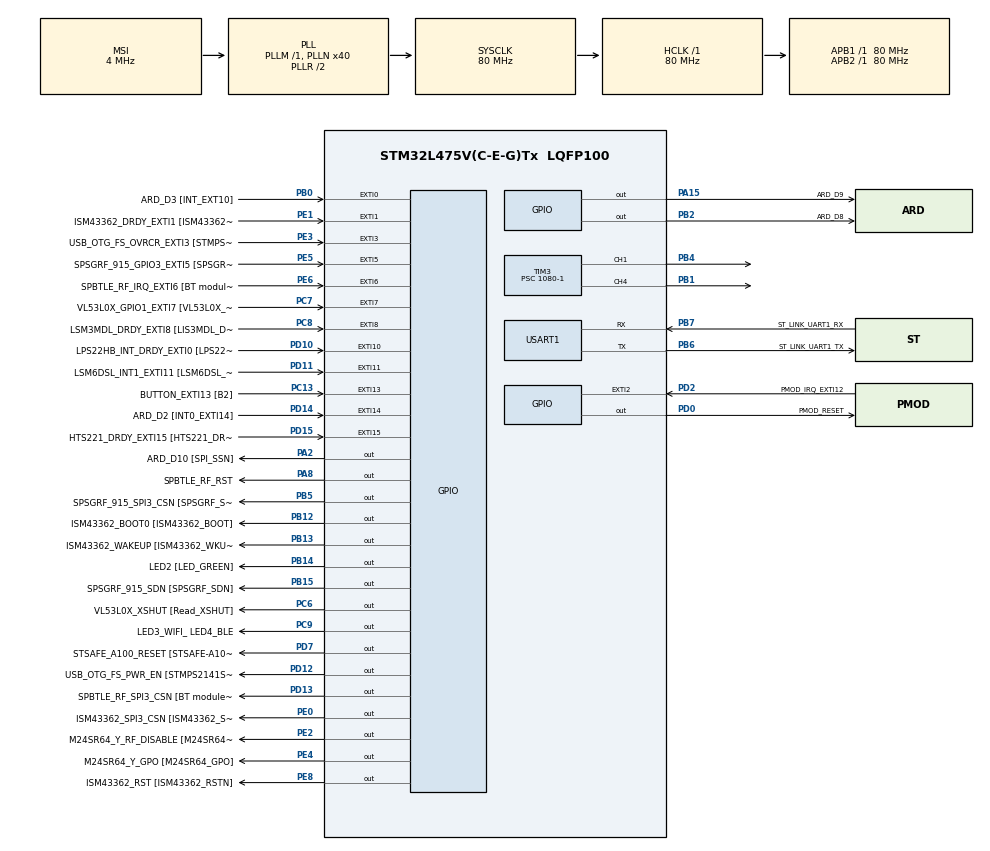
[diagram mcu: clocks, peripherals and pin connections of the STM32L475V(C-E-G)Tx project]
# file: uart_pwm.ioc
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Mcu.Family=STM32L4
Mcu.Name=STM32L475V(C-E-G)Tx
Mcu.Package=LQFP100
NVIC.EXTI15_10_IRQn=true\:0\:0\:false\:false\:true\:true\:true
NVIC.EXTI9_5_IRQn=true\:0\:0\:false\:false\:true\:true\:true
NVIC.PriorityGroup=NVIC_PRIORITYGROUP_4
PA0.GPIO_Label=ARD_D1 [UART4_TX]
PA0.Signal=UART4_TX
PA1.GPIO_Label=ARD_D0 [UART4_RX]
PA1.Signal=UART4_RX
PA10.GPIO_Label=USB_OTG_FS_ID
PA10.Signal=USB_OTG_FS_ID
PA11.GPIO_Label=USB_OTG_FS_DM
PA11.Signal=USB_OTG_FS_DM
PA12.GPIO_Label=USB_OTG_FS_DP
PA12.Signal=USB_OTG_FS_DP
PA13\ (JTMS-SWDIO).GPIO_Label=SYS_JTMS_SWDIO
PA13\ (JTMS-SWDIO).Signal=SYS_JTMS-SWDIO
PA14\ (JTCK-SWCLK).GPIO_Label=SYS_JTCK_SWCLK
PA14\ (JTCK-SWCLK).Signal=SYS_JTCK-SWCLK
PA15\ (JTDI).GPIO_Label=ARD_D9
PA15\ (JTDI).Signal=GPIO_Output
PA2.GPIO_Label=ARD_D10 [SPI_SSN]
PA2.Signal=GPIO_Output
PA3.GPIO_Label=ARD_D4
PA3.Signal=S_TIM2_CH4
PA4.GPIO_Label=ARD_D7
PA4.Signal=ADCx_IN9
PA5.GPIO_Label=ARD_D13 [SPI1_SCK]
PA5.Signal=SPI1_SCK
PA6.GPIO_Label=ARD_D12 [SPI1_MISO]
PA6.Signal=SPI1_MISO
PA7.GPIO_Label=ARD_D11 [SPI1_MOSI]
PA7.Signal=SPI1_MOSI
PA8.GPIO_Label=SPBTLE_RF_RST
PA8.Signal=GPIO_Output
PA9.GPIO_Label=USB_OTG_FS_VBUS [STMPS2141STR_OUT]
PA9.Signal=USB_OTG_FS_VBUS
PB0.GPIO_Label=ARD_D3 [INT_EXT10]
PB0.Signal=GPXTI0
PB1.Signal=S_TIM3_CH4
PB10.GPIO_Label=INTERNAL_I2C2_SCL [VL53L0X_SCL]
PB10.Signal=I2C2_SCL
PB11.GPIO_Label=INTERNAL_I2C2_SDA [VL53L0X_SDA]
PB11.Signal=I2C2_SDA
PB12.GPIO_Label=ISM43362_BOOT0 [ISM43362_BOOT]
PB12.Signal=GPIO_Output
PB13.GPIO_Label=ISM43362_WAKEUP [ISM43362_WKUP]
PB13.Signal=GPIO_Output
PB14.GPIO_Label=LED2 [LED_GREEN]
PB14.Signal=GPIO_Output
PB15.GPIO_Label=SPSGRF_915_SDN [SPSGRF_SDN]
PB15.Signal=GPIO_Output
PB2.GPIO_Label=ARD_D8
PB2.Signal=GPIO_Output
PB3\ (JTDO-TRACESWO).GPIO_Label=SYS_JTD0_SWO
PB3\ (JTDO-TRACESWO).Signal=SYS_JTDO-SWO
PB4\ (NJTRST).Signal=S_TIM3_CH1
PB5.GPIO_Label=SPSGRF_915_SPI3_CSN [SPSGRF_SPI_CS]
PB5.PinState=GPIO_PIN_SET
PB5.Signal=GPIO_Output
PB6.GPIO_Label=ST_LINK_UART1_TX
PB6.Mode=Asynchronous
PB6.Signal=USART1_TX
PB7.GPIO_Label=ST_LINK_UART1_RX
PB7.Mode=Asynchronous
PB7.Signal=USART1_RX
PB8.GPIO_Label=ARD_D15 [I2C1_SCL]
PB8.Signal=I2C1_SCL
PB9.GPIO_Label=ARD_D14 [I2C1_SDA]
PB9.Signal=I2C1_SDA
PC0.GPIO_Label=ARD_A5 [ADC]
PC0.Signal=ADCx_IN1
PC1.GPIO_Label=ARD_A4 [ADC]
PC1.Signal=ADCx_IN2
PC10.GPIO_Label=INTERNAL_SPI3_SCK [BT module_SPI_SCLK]
PC10.Signal=SPI3_SCK
PC11.GPIO_Label=INTERNAL_SPI3_MISO [BT module_SPI_MISO]
PC11.Signal=SPI3_MISO
PC12.GPIO_Label=INTERNAL_SPI3_MOSI [BT module_SPI_MOSI]
PC12.Signal=SPI3_MOSI
PC13.GPIO_Label=BUTTON_EXTI13 [B2]
PC13.GPIO_ModeDefaultEXTI=GPIO_MODE_IT_FALLING
PC13.Signal=GPXTI13
PC14-OSC32_IN\ (PC14).Signal=RCC_OSC32_IN
PC15-OSC32_OUT\ (PC15).Signal=RCC_OSC32_OUT
PC2.GPIO_Label=ARD_A3 [ADC]
PC2.Signal=ADCx_IN3
PC3.GPIO_Label=ARD_A2 [ADC]
PC3.Signal=ADCx_IN4
PC4.GPIO_Label=ARD_A1 [ADC]
PC4.Signal=ADCx_IN13
PC5.GPIO_Label=ARD_A0 [ADC]
PC5.Signal=ADCx_IN14
PC6.GPIO_Label=VL53L0X_XSHUT [Read_XSHUT]
PC6.Signal=GPIO_Output
PC7.GPIO_Label=VL53L0X_GPIO1_EXTI7 [VL53L0X_GPIO1]
PC7.Signal=GPXTI7
PC8.GPIO_Label=LSM3MDL_DRDY_EXTI8 [LIS3MDL_DRDY]
PC8.Signal=GPXTI8
PC9.GPIO_Label=LED3_WIFI_ LED4_BLE
PC9.Signal=GPIO_Output
PD0.GPIO_Label=PMOD_RESET
PD0.Signal=GPIO_Output
PD1.GPIO_Label=PMOD_SPI2_SCK
PD1.Signal=SPI2_SCK
PD10.GPIO_Label=LPS22HB_INT_DRDY_EXTI0 [LPS22HB_INT_DRDY] 
PD10.Signal=GPXTI10
PD11.GPIO_Label=LSM6DSL_INT1_EXTI11 [LSM6DSL_INT1]
PD11.Signal=GPXTI11
PD12.GPIO_Label=USB_OTG_FS_PWR_EN [STMPS2141STR_EN]
PD12.Signal=GPIO_Output
PD13.GPIO_Label=SPBTLE_RF_SPI3_CSN [BT module_SPI_CS]
PD13.PinState=GPIO_PIN_SET
PD13.Signal=GPIO_Output
PD14.GPIO_Label=ARD_D2 [INT0_EXTI14]
PD14.Signal=GPXTI14
PD15.GPIO_Label=HTS221_DRDY_EXTI15 [HTS221_DRDY]
PD15.Signal=GPXTI15
PD2.GPIO_Label=PMOD_IRQ_EXTI12
PD2.Signal=GPXTI2
PD3.GPIO_Label=PMOD_UART2_CTS
PD3.Signal=USART2_CTS
PD4.GPIO_Label=PMOD_UART2_RTS
PD4.Signal=USART2_RTS
PD5.GPIO_Label=PMOD_UART2_TX
PD5.Signal=USART2_TX
PD6.GPIO_Label=PMOD_UART2_RX
PD6.Signal=USART2_RX
PD7.GPIO_Label=STSAFE_A100_RESET [STSAFE-A100_RESET]
PD7.Signal=GPIO_Output
PD8.GPIO_Label=INTERNAL_UART3_TX [ISM43362_RX]
PD8.Signal=USART3_TX
PD9.GPIO_Label=INTERNAL_UART3_RX [ISM43362_TX]
PD9.Signal=USART3_RX
PE0.GPIO_Label=ISM43362_SPI3_CSN [ISM43362_SSN]
PE0.PinState=GPIO_PIN_SET
PE0.Signal=GPIO_Output
PE1.GPIO_Label=ISM43362_DRDY_EXTI1 [ISM43362_DATARDY]
PE1.Signal=GPXTI1
PE10.GPIO_Label=QUADSPI_CLK [MX25R6435F_SCLK]
PE10.Signal=QUADSPI_CLK
PE11.GPIO_Label=QUADSPI_NCS [MX25R6435F_SCLK]
PE11.Signal=QUADSPI_NCS
PE12.GPIO_Label=OQUADSPI_BK1_IO0 [MX25R6435F_IO0]
PE12.Signal=QUADSPI_BK1_IO0
PE13.GPIO_Label=QUADSPI_BK1_IO1 [MX25R6435F_IO1]
PE13.Signal=QUADSPI_BK1_IO1
PE14.GPIO_Label=QUAD_SPI_BK1_IO2 [MX25R6435F_IO2]
PE14.Signal=QUADSPI_BK1_IO2
PE15.GPIO_Label=QUAD_SPI_BK1_IO3 [MX25R6435F_IO3]
PE15.Signal=QUADSPI_BK1_IO3
PE2.GPIO_Label=M24SR64_Y_RF_DISABLE [M24SR64_RFDIS]
PE2.Signal=GPIO_Output
PE3.GPIO_Label=USB_OTG_FS_OVRCR_EXTI3 [STMPS2141STR_FAULT]
PE3.Signal=GPXTI3
PE4.GPIO_Label=M24SR64_Y_GPO [M24SR64_GPO]
PE4.Signal=GPIO_Output
PE5.GPIO_Label=SPSGRF_915_GPIO3_EXTI5 [SPSGRF_GPIO_3]
PE5.Signal=GPXTI5
PE6.GPIO_Label=SPBTLE_RF_IRQ_EXTI6 [BT module_SPI_IRQ]
PE6.Signal=GPXTI6
PE7.GPIO_Label=DFSDM1_DATIN2 [MP34DT01_DOUT]
PE7.Signal=S_DATAIN2DFSDM1
PE8.GPIO_Label=ISM43362_RST [ISM43362_RSTN]
PE8.Signal=GPIO_Output
PE9.GPIO_Label=DFSDM1_CKOUT [MP34DT01_CLK]
PE9.Signal=S_CKOUTDFSDM1
ProjectManager.HeapSize=0x200
ProjectManager.StackSize=0x400
ProjectManager.TargetToolchain=SW4STM32
RCC.ADCFreq_Value=48000000
RCC.AHBFreq_Value=80000000
RCC.APB1Freq_Value=80000000
RCC.APB1TimFreq_Value=80000000
RCC.APB2Freq_Value=80000000
RCC.APB2TimFreq_Value=80000000
RCC.CortexFreq_Value=80000000
RCC.HCLKFreq_Value=80000000
RCC.HSE_VALUE=8000000
RCC.HSI_VALUE=16000000
RCC.LSE_VALUE=32768
RCC.MSI_VALUE=4000000
RCC.PLLN=40
RCC.PLLSAI1N=24
RCC.SYSCLKFreq_VALUE=80000000
RCC.SYSCLKSource=RCC_SYSCLKSOURCE_PLLCLK
RCC.USBFreq_Value=48000000
RCC.VCOOutputFreq_Value=160000000
SH.ADCx_IN1.0=ADC1_IN1
SH.ADCx_IN13.0=ADC1_IN13
SH.ADCx_IN14.0=ADC1_IN14
SH.ADCx_IN2.0=ADC1_IN2
SH.ADCx_IN3.0=ADC1_IN3
SH.ADCx_IN4.0=ADC1_IN4
SH.ADCx_IN9.0=ADC1_IN9
SH.S_CKOUTDFSDM1.0=DFSDM1_CKOUT
SH.S_DATAIN2DFSDM1.0=DFSDM1_DATIN2
SH.S_TIM2_CH4.0=TIM2_CH4
SH.S_TIM3_CH1.0=TIM3_CH1,PWM Generation1 CH1
SH.S_TIM3_CH4.0=TIM3_CH4,PWM Generation4 CH4
TIM3.Channel-PWM\ Generation1\ CH1=TIM_CHANNEL_1
TIM3.Channel-PWM\ Generation4\ CH4=TIM_CHANNEL_4
TIM3.Period=2000-1
TIM3.Prescaler=1080-1
USART1.VirtualMode-Asynchronous=VM_ASYNC
board=B-L475E-IOT01A

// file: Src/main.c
/* USER CODE BEGIN Header */
/**
 ******************************************************************************
 * @file           : main.c
 * @brief          : Main program body
 ******************************************************************************
 * @attention
 *
 * <h2><center>&copy; Copyright (c) 2019 STMicroelectronics.
 * All rights reserved.</center></h2>
 *
 * This software component is licensed by ST under BSD 3-Clause license,
 * the "License"; You may not use this file except in compliance with the
 * License. You may obtain a copy of the License at:
 *                        opensource.org/licenses/BSD-3-Clause
 *
 ******************************************************************************
 */
/* USER CODE END Header */

#include "main.h"

TIM_HandleTypeDef htim3;

UART_HandleTypeDef huart1;

void SystemClock_Config(void);
static void MX_GPIO_Init(void);
static void MX_TIM3_Init(void);
static void MX_USART1_UART_Init(void);
void user_pwm_setvalue(uint16_t value);

int main(void) {

	/* MCU Configuration--------------------------------------------------------*/

	/* Reset of all peripherals, Initializes the Flash interface and the Systick. */
	HAL_Init();

	/* Configure the system clock */
	SystemClock_Config();

	/* Initialize all configured peripherals */
	MX_GPIO_Init();
	MX_TIM3_Init();
	MX_USART1_UART_Init();
	/* USER CODE BEGIN 2 */
	static uint16_t val1 = 660; //680        // variable to store the read value
	static uint16_t val2 = 665;
	char input;
	/* USER CODE END 2 */
	/* Infinite loop */
	while (1) {
		HAL_UART_Receive(&huart1, (uint8_t *) &input, sizeof(input), HAL_MAX_DELAY);
		//HAL_UART_Transmit(&huart1, (uint8_t *) &input, sizeof(char), 10);

		  char inChar = input;
		      switch(inChar)
		      {
		        case('w'): val1=val1+30;
		        if(val1>760)
		        {
		          val1=760;
		        }
		        break;
		         case('s'): val1=val1-30;
		        if(val1<550)
		        {
		          val1=550;
		        }
		        break;
		        case('a'):val2=val2-10;
		        if(val2<550)
		        {
		          val2=550;
		        }
		        break;
		        case('d'):val2=val2+10;
		        if(val2>710)
		        {
		          val2=710;
		        }
		        break;
		      }

		      HAL_UART_Transmit(&huart1, (uint16_t *) &val1, sizeof(uint16_t *)&val1, 10);

		      user_pwm_setvalue(val1);
		      user_pwm_setvalue(val2);
		  }

	}

void user_pwm_setvalue(uint16_t value)
{
    TIM_OC_InitTypeDef sConfigOC;

    sConfigOC.OCMode = TIM_OCMODE_PWM1;
    sConfigOC.Pulse = value;
    sConfigOC.OCPolarity = TIM_OCPOLARITY_HIGH;
    sConfigOC.OCFastMode = TIM_OCFAST_DISABLE;
    HAL_TIM_PWM_ConfigChannel(&htim3, &sConfigOC, TIM_CHANNEL_1);
    HAL_TIM_PWM_Start(&htim3, TIM_CHANNEL_1);
}

void SystemClock_Config(void) {
	RCC_OscInitTypeDef RCC_OscInitStruct = { 0 };
	RCC_ClkInitTypeDef RCC_ClkInitStruct = { 0 };
	RCC_PeriphCLKInitTypeDef PeriphClkInit = { 0 };

	/** Initializes the CPU, AHB and APB busses clocks
	 */
	RCC_OscInitStruct.OscillatorType = RCC_OSCILLATORTYPE_MSI;
	RCC_OscInitStruct.MSIState = RCC_MSI_ON;
	RCC_OscInitStruct.MSICalibrationValue = 0;
	RCC_OscInitStruct.MSIClockRange = RCC_MSIRANGE_6;
	RCC_OscInitStruct.PLL.PLLState = RCC_PLL_ON;
	RCC_OscInitStruct.PLL.PLLSource = RCC_PLLSOURCE_MSI;
	RCC_OscInitStruct.PLL.PLLM = 1;
	RCC_OscInitStruct.PLL.PLLN = 40;
	RCC_OscInitStruct.PLL.PLLP = RCC_PLLP_DIV7;
	RCC_OscInitStruct.PLL.PLLQ = RCC_PLLQ_DIV2;
	RCC_OscInitStruct.PLL.PLLR = RCC_PLLR_DIV2;
	if (HAL_RCC_OscConfig(&RCC_OscInitStruct) != HAL_OK) {
		Error_Handler();
	}
	/** Initializes the CPU, AHB and APB busses clocks
	 */
	RCC_ClkInitStruct.ClockType = RCC_CLOCKTYPE_HCLK | RCC_CLOCKTYPE_SYSCLK
			| RCC_CLOCKTYPE_PCLK1 | RCC_CLOCKTYPE_PCLK2;
	RCC_ClkInitStruct.SYSCLKSource = RCC_SYSCLKSOURCE_PLLCLK;
	RCC_ClkInitStruct.AHBCLKDivider = RCC_SYSCLK_DIV1;
	RCC_ClkInitStruct.APB1CLKDivider = RCC_HCLK_DIV1;
	RCC_ClkInitStruct.APB2CLKDivider = RCC_HCLK_DIV1;

	if (HAL_RCC_ClockConfig(&RCC_ClkInitStruct, FLASH_LATENCY_4) != HAL_OK) {
		Error_Handler();
	}
	PeriphClkInit.PeriphClockSelection = RCC_PERIPHCLK_USART1;
	PeriphClkInit.Usart1ClockSelection = RCC_USART1CLKSOURCE_PCLK2;
	if (HAL_RCCEx_PeriphCLKConfig(&PeriphClkInit) != HAL_OK) {
		Error_Handler();
	}
	/** Configure the main internal regulator output voltage
	 */
	if (HAL_PWREx_ControlVoltageScaling(PWR_REGULATOR_VOLTAGE_SCALE1)
			!= HAL_OK) {
		Error_Handler();
	}
}

static void MX_TIM3_Init(void) {

	TIM_MasterConfigTypeDef sMasterConfig = { 0 };
	TIM_OC_InitTypeDef sConfigOC = { 0 };

	htim3.Instance = TIM3;
	htim3.Init.Prescaler = 1080 - 1;
	htim3.Init.CounterMode = TIM_COUNTERMODE_UP;
	htim3.Init.Period = 2000 - 1;
	htim3.Init.ClockDivision = TIM_CLOCKDIVISION_DIV1;
	htim3.Init.AutoReloadPreload = TIM_AUTORELOAD_PRELOAD_DISABLE;
	if (HAL_TIM_PWM_Init(&htim3) != HAL_OK) {
		Error_Handler();
	}
	sMasterConfig.MasterOutputTrigger = TIM_TRGO_RESET;
	sMasterConfig.MasterSlaveMode = TIM_MASTERSLAVEMODE_DISABLE;
	if (HAL_TIMEx_MasterConfigSynchronization(&htim3, &sMasterConfig)
			!= HAL_OK) {
		Error_Handler();
	}
	sConfigOC.OCMode = TIM_OCMODE_PWM1;
	sConfigOC.Pulse = 0;
	sConfigOC.OCPolarity = TIM_OCPOLARITY_HIGH;
	sConfigOC.OCFastMode = TIM_OCFAST_DISABLE;
	if (HAL_TIM_PWM_ConfigChannel(&htim3, &sConfigOC, TIM_CHANNEL_1)
			!= HAL_OK) {
		Error_Handler();
	}
	if (HAL_TIM_PWM_ConfigChannel(&htim3, &sConfigOC, TIM_CHANNEL_4)
			!= HAL_OK) {
		Error_Handler();
	}
	HAL_TIM_MspPostInit(&htim3);

}

static void MX_USART1_UART_Init(void) {

	huart1.Instance = USART1;
	huart1.Init.BaudRate = 115200;
	huart1.Init.WordLength = UART_WORDLENGTH_8B;
	huart1.Init.StopBits = UART_STOPBITS_1;
	huart1.Init.Parity = UART_PARITY_NONE;
	huart1.Init.Mode = UART_MODE_TX_RX;
	huart1.Init.HwFlowCtl = UART_HWCONTROL_NONE;
	huart1.Init.OverSampling = UART_OVERSAMPLING_16;
	huart1.Init.OneBitSampling = UART_ONE_BIT_SAMPLE_DISABLE;
	huart1.AdvancedInit.AdvFeatureInit = UART_ADVFEATURE_NO_INIT;
	if (HAL_UART_Init(&huart1) != HAL_OK) {
		Error_Handler();
	}

}

static void MX_GPIO_Init(void) {
	GPIO_InitTypeDef GPIO_InitStruct = { 0 };

	/* GPIO Ports Clock Enable */
	__HAL_RCC_GPIOE_CLK_ENABLE()
	;
	__HAL_RCC_GPIOC_CLK_ENABLE()
	;
	__HAL_RCC_GPIOA_CLK_ENABLE()
	;
	__HAL_RCC_GPIOB_CLK_ENABLE()
	;
	__HAL_RCC_GPIOD_CLK_ENABLE()
	;

	/*Configure GPIO pin Output Level */
	HAL_GPIO_WritePin(GPIOE,
			M24SR64_Y_RF_DISABLE_Pin | M24SR64_Y_GPO_Pin | ISM43362_RST_Pin,
			GPIO_PIN_RESET);

	/*Configure GPIO pin Output Level */
	HAL_GPIO_WritePin(GPIOA, ARD_D10_Pin | SPBTLE_RF_RST_Pin | ARD_D9_Pin,
			GPIO_PIN_RESET);

	/*Configure GPIO pin Output Level */
	HAL_GPIO_WritePin(GPIOB,
			ARD_D8_Pin | ISM43362_BOOT0_Pin | ISM43362_WAKEUP_Pin | LED2_Pin
					| SPSGRF_915_SDN_Pin, GPIO_PIN_RESET);

	/*Configure GPIO pin Output Level */
	HAL_GPIO_WritePin(GPIOD,
			USB_OTG_FS_PWR_EN_Pin | PMOD_RESET_Pin | STSAFE_A100_RESET_Pin,
			GPIO_PIN_RESET);

	/*Configure GPIO pin Output Level */
	HAL_GPIO_WritePin(SPBTLE_RF_SPI3_CSN_GPIO_Port, SPBTLE_RF_SPI3_CSN_Pin,
			GPIO_PIN_SET);

	/*Configure GPIO pin Output Level */
	HAL_GPIO_WritePin(GPIOC, VL53L0X_XSHUT_Pin | LED3_WIFI__LED4_BLE_Pin,
			GPIO_PIN_RESET);

	/*Configure GPIO pin Output Level */
	HAL_GPIO_WritePin(SPSGRF_915_SPI3_CSN_GPIO_Port, SPSGRF_915_SPI3_CSN_Pin,
			GPIO_PIN_SET);

	/*Configure GPIO pin Output Level */
	HAL_GPIO_WritePin(ISM43362_SPI3_CSN_GPIO_Port, ISM43362_SPI3_CSN_Pin,
			GPIO_PIN_SET);

	/*Configure GPIO pins : M24SR64_Y_RF_DISABLE_Pin M24SR64_Y_GPO_Pin ISM43362_RST_Pin ISM43362_SPI3_CSN_Pin */
	GPIO_InitStruct.Pin = M24SR64_Y_RF_DISABLE_Pin | M24SR64_Y_GPO_Pin
			| ISM43362_RST_Pin | ISM43362_SPI3_CSN_Pin;
	GPIO_InitStruct.Mode = GPIO_MODE_OUTPUT_PP;
	GPIO_InitStruct.Pull = GPIO_NOPULL;
	GPIO_InitStruct.Speed = GPIO_SPEED_FREQ_LOW;
	HAL_GPIO_Init(GPIOE, &GPIO_InitStruct);

	/*Configure GPIO pins : USB_OTG_FS_OVRCR_EXTI3_Pin SPSGRF_915_GPIO3_EXTI5_Pin SPBTLE_RF_IRQ_EXTI6_Pin ISM43362_DRDY_EXTI1_Pin */
	GPIO_InitStruct.Pin = USB_OTG_FS_OVRCR_EXTI3_Pin
			| SPSGRF_915_GPIO3_EXTI5_Pin | SPBTLE_RF_IRQ_EXTI6_Pin
			| ISM43362_DRDY_EXTI1_Pin;
	GPIO_InitStruct.Mode = GPIO_MODE_IT_RISING;
	GPIO_InitStruct.Pull = GPIO_NOPULL;
	HAL_GPIO_Init(GPIOE, &GPIO_InitStruct);

	/*Configure GPIO pin : BUTTON_EXTI13_Pin */
	GPIO_InitStruct.Pin = BUTTON_EXTI13_Pin;
	GPIO_InitStruct.Mode = GPIO_MODE_IT_FALLING;
	GPIO_InitStruct.Pull = GPIO_NOPULL;
	HAL_GPIO_Init(BUTTON_EXTI13_GPIO_Port, &GPIO_InitStruct);

	/*Configure GPIO pins : ARD_A5_Pin ARD_A4_Pin ARD_A3_Pin ARD_A2_Pin
	 ARD_A1_Pin ARD_A0_Pin */
	GPIO_InitStruct.Pin = ARD_A5_Pin | ARD_A4_Pin | ARD_A3_Pin | ARD_A2_Pin
			| ARD_A1_Pin | ARD_A0_Pin;
	GPIO_InitStruct.Mode = GPIO_MODE_ANALOG_ADC_CONTROL;
	GPIO_InitStruct.Pull = GPIO_NOPULL;
	HAL_GPIO_Init(GPIOC, &GPIO_InitStruct);

	/*Configure GPIO pins : ARD_D1_Pin ARD_D0_Pin */
	GPIO_InitStruct.Pin = ARD_D1_Pin | ARD_D0_Pin;
	GPIO_InitStruct.Mode = GPIO_MODE_AF_PP;
	GPIO_InitStruct.Pull = GPIO_NOPULL;
	GPIO_InitStruct.Speed = GPIO_SPEED_FREQ_VERY_HIGH;
	GPIO_InitStruct.Alternate = GPIO_AF8_UART4;
	HAL_GPIO_Init(GPIOA, &GPIO_InitStruct);

	/*Configure GPIO pins : ARD_D10_Pin SPBTLE_RF_RST_Pin ARD_D9_Pin */
	GPIO_InitStruct.Pin = ARD_D10_Pin | SPBTLE_RF_RST_Pin | ARD_D9_Pin;
	GPIO_InitStruct.Mode = GPIO_MODE_OUTPUT_PP;
	GPIO_InitStruct.Pull = GPIO_NOPULL;
	GPIO_InitStruct.Speed = GPIO_SPEED_FREQ_LOW;
	HAL_GPIO_Init(GPIOA, &GPIO_InitStruct);

	/*Configure GPIO pin : ARD_D4_Pin */
	GPIO_InitStruct.Pin = ARD_D4_Pin;
	GPIO_InitStruct.Mode = GPIO_MODE_AF_PP;
	GPIO_InitStruct.Pull = GPIO_NOPULL;
	GPIO_InitStruct.Speed = GPIO_SPEED_FREQ_LOW;
	GPIO_InitStruct.Alternate = GPIO_AF1_TIM2;
	HAL_GPIO_Init(ARD_D4_GPIO_Port, &GPIO_InitStruct);

	/*Configure GPIO pin : ARD_D7_Pin */
	GPIO_InitStruct.Pin = ARD_D7_Pin;
	GPIO_InitStruct.Mode = GPIO_MODE_ANALOG_ADC_CONTROL;
	GPIO_InitStruct.Pull = GPIO_NOPULL;
	HAL_GPIO_Init(ARD_D7_GPIO_Port, &GPIO_InitStruct);

	/*Configure GPIO pins : ARD_D13_Pin ARD_D12_Pin ARD_D11_Pin */
	GPIO_InitStruct.Pin = ARD_D13_Pin | ARD_D12_Pin | ARD_D11_Pin;
	GPIO_InitStruct.Mode = GPIO_MODE_AF_PP;
	GPIO_InitStruct.Pull = GPIO_NOPULL;
	GPIO_InitStruct.Speed = GPIO_SPEED_FREQ_VERY_HIGH;
	GPIO_InitStruct.Alternate = GPIO_AF5_SPI1;
	HAL_GPIO_Init(GPIOA, &GPIO_InitStruct);

	/*Configure GPIO pin : ARD_D3_Pin */
	GPIO_InitStruct.Pin = ARD_D3_Pin;
	GPIO_InitStruct.Mode = GPIO_MODE_IT_RISING;
	GPIO_InitStruct.Pull = GPIO_NOPULL;
	HAL_GPIO_Init(ARD_D3_GPIO_Port, &GPIO_InitStruct);

	/*Configure GPIO pins : ARD_D8_Pin ISM43362_BOOT0_Pin ISM43362_WAKEUP_Pin LED2_Pin
	 SPSGRF_915_SDN_Pin SPSGRF_915_SPI3_CSN_Pin */
	GPIO_InitStruct.Pin = ARD_D8_Pin | ISM43362_BOOT0_Pin | ISM43362_WAKEUP_Pin
			| LED2_Pin | SPSGRF_915_SDN_Pin | SPSGRF_915_SPI3_CSN_Pin;
	GPIO_InitStruct.Mode = GPIO_MODE_OUTPUT_PP;
	GPIO_InitStruct.Pull = GPIO_NOPULL;
	GPIO_InitStruct.Speed = GPIO_SPEED_FREQ_LOW;
	HAL_GPIO_Init(GPIOB, &GPIO_InitStruct);

	/*Configure GPIO pins : DFSDM1_DATIN2_Pin DFSDM1_CKOUT_Pin */
	GPIO_InitStruct.Pin = DFSDM1_DATIN2_Pin | DFSDM1_CKOUT_Pin;
	GPIO_InitStruct.Mode = GPIO_MODE_AF_PP;
	GPIO_InitStruct.Pull = GPIO_NOPULL;
	GPIO_InitStruct.Speed = GPIO_SPEED_FREQ_LOW;
	GPIO_InitStruct.Alternate = GPIO_AF6_DFSDM1;
	HAL_GPIO_Init(GPIOE, &GPIO_InitStruct);

	/*Configure GPIO pins : QUADSPI_CLK_Pin QUADSPI_NCS_Pin OQUADSPI_BK1_IO0_Pin QUADSPI_BK1_IO1_Pin
	 QUAD_SPI_BK1_IO2_Pin QUAD_SPI_BK1_IO3_Pin */
	GPIO_InitStruct.Pin = QUADSPI_CLK_Pin | QUADSPI_NCS_Pin
			| OQUADSPI_BK1_IO0_Pin | QUADSPI_BK1_IO1_Pin | QUAD_SPI_BK1_IO2_Pin
			| QUAD_SPI_BK1_IO3_Pin;
	GPIO_InitStruct.Mode = GPIO_MODE_AF_PP;
	GPIO_InitStruct.Pull = GPIO_NOPULL;
	GPIO_InitStruct.Speed = GPIO_SPEED_FREQ_VERY_HIGH;
	GPIO_InitStruct.Alternate = GPIO_AF10_QUADSPI;
	HAL_GPIO_Init(GPIOE, &GPIO_InitStruct);

	/*Configure GPIO pins : INTERNAL_I2C2_SCL_Pin INTERNAL_I2C2_SDA_Pin */
	GPIO_InitStruct.Pin = INTERNAL_I2C2_SCL_Pin | INTERNAL_I2C2_SDA_Pin;
	GPIO_InitStruct.Mode = GPIO_MODE_AF_OD;
	GPIO_InitStruct.Pull = GPIO_PULLUP;
	GPIO_InitStruct.Speed = GPIO_SPEED_FREQ_VERY_HIGH;
	GPIO_InitStruct.Alternate = GPIO_AF4_I2C2;
	HAL_GPIO_Init(GPIOB, &GPIO_InitStruct);

	/*Configure GPIO pins : INTERNAL_UART3_TX_Pin INTERNAL_UART3_RX_Pin */
	GPIO_InitStruct.Pin = INTERNAL_UART3_TX_Pin | INTERNAL_UART3_RX_Pin;
	GPIO_InitStruct.Mode = GPIO_MODE_AF_PP;
	GPIO_InitStruct.Pull = GPIO_NOPULL;
	GPIO_InitStruct.Speed = GPIO_SPEED_FREQ_VERY_HIGH;
	GPIO_InitStruct.Alternate = GPIO_AF7_USART3;
	HAL_GPIO_Init(GPIOD, &GPIO_InitStruct);

	/*Configure GPIO pins : LPS22HB_INT_DRDY_EXTI0_Pin LSM6DSL_INT1_EXTI11_Pin ARD_D2_Pin HTS221_DRDY_EXTI15_Pin
	 PMOD_IRQ_EXTI12_Pin */
	GPIO_InitStruct.Pin = LPS22HB_INT_DRDY_EXTI0_Pin | LSM6DSL_INT1_EXTI11_Pin
			| ARD_D2_Pin | HTS221_DRDY_EXTI15_Pin | PMOD_IRQ_EXTI12_Pin;
	GPIO_InitStruct.Mode = GPIO_MODE_IT_RISING;
	GPIO_InitStruct.Pull = GPIO_NOPULL;
	HAL_GPIO_Init(GPIOD, &GPIO_InitStruct);

	/*Configure GPIO pins : USB_OTG_FS_PWR_EN_Pin SPBTLE_RF_SPI3_CSN_Pin PMOD_RESET_Pin STSAFE_A100_RESET_Pin */
	GPIO_InitStruct.Pin = USB_OTG_FS_PWR_EN_Pin | SPBTLE_RF_SPI3_CSN_Pin
			| PMOD_RESET_Pin | STSAFE_A100_RESET_Pin;
	GPIO_InitStruct.Mode = GPIO_MODE_OUTPUT_PP;
	GPIO_InitStruct.Pull = GPIO_NOPULL;
	GPIO_InitStruct.Speed = GPIO_SPEED_FREQ_LOW;
	HAL_GPIO_Init(GPIOD, &GPIO_InitStruct);

	/*Configure GPIO pins : VL53L0X_XSHUT_Pin LED3_WIFI__LED4_BLE_Pin */
	GPIO_InitStruct.Pin = VL53L0X_XSHUT_Pin | LED3_WIFI__LED4_BLE_Pin;
	GPIO_InitStruct.Mode = GPIO_MODE_OUTPUT_PP;
	GPIO_InitStruct.Pull = GPIO_NOPULL;
	GPIO_InitStruct.Speed = GPIO_SPEED_FREQ_LOW;
	HAL_GPIO_Init(GPIOC, &GPIO_InitStruct);

	/*Configure GPIO pins : VL53L0X_GPIO1_EXTI7_Pin LSM3MDL_DRDY_EXTI8_Pin */
	GPIO_InitStruct.Pin = VL53L0X_GPIO1_EXTI7_Pin | LSM3MDL_DRDY_EXTI8_Pin;
	GPIO_InitStruct.Mode = GPIO_MODE_IT_RISING;
	GPIO_InitStruct.Pull = GPIO_NOPULL;
	HAL_GPIO_Init(GPIOC, &GPIO_InitStruct);

	/*Configure GPIO pin : USB_OTG_FS_VBUS_Pin */
	GPIO_InitStruct.Pin = USB_OTG_FS_VBUS_Pin;
	GPIO_InitStruct.Mode = GPIO_MODE_INPUT;
	GPIO_InitStruct.Pull = GPIO_NOPULL;
	HAL_GPIO_Init(USB_OTG_FS_VBUS_GPIO_Port, &GPIO_InitStruct);

	/*Configure GPIO pins : USB_OTG_FS_ID_Pin USB_OTG_FS_DM_Pin USB_OTG_FS_DP_Pin */
	GPIO_InitStruct.Pin = USB_OTG_FS_ID_Pin | USB_OTG_FS_DM_Pin
			| USB_OTG_FS_DP_Pin;
	GPIO_InitStruct.Mode = GPIO_MODE_AF_PP;
	GPIO_InitStruct.Pull = GPIO_NOPULL;
	GPIO_InitStruct.Speed = GPIO_SPEED_FREQ_VERY_HIGH;
	GPIO_InitStruct.Alternate = GPIO_AF10_OTG_FS;
	HAL_GPIO_Init(GPIOA, &GPIO_InitStruct);

	/*Configure GPIO pins : INTERNAL_SPI3_SCK_Pin INTERNAL_SPI3_MISO_Pin INTERNAL_SPI3_MOSI_Pin */
	GPIO_InitStruct.Pin = INTERNAL_SPI3_SCK_Pin | INTERNAL_SPI3_MISO_Pin
			| INTERNAL_SPI3_MOSI_Pin;
	GPIO_InitStruct.Mode = GPIO_MODE_AF_PP;
	GPIO_InitStruct.Pull = GPIO_NOPULL;
	GPIO_InitStruct.Speed = GPIO_SPEED_FREQ_VERY_HIGH;
	GPIO_InitStruct.Alternate = GPIO_AF6_SPI3;
	HAL_GPIO_Init(GPIOC, &GPIO_InitStruct);

	/*Configure GPIO pin : PMOD_SPI2_SCK_Pin */
	GPIO_InitStruct.Pin = PMOD_SPI2_SCK_Pin;
	GPIO_InitStruct.Mode = GPIO_MODE_AF_PP;
	GPIO_InitStruct.Pull = GPIO_NOPULL;
	GPIO_InitStruct.Speed = GPIO_SPEED_FREQ_VERY_HIGH;
	GPIO_InitStruct.Alternate = GPIO_AF5_SPI2;
	HAL_GPIO_Init(PMOD_SPI2_SCK_GPIO_Port, &GPIO_InitStruct);

	/*Configure GPIO pins : PMOD_UART2_CTS_Pin PMOD_UART2_RTS_Pin PMOD_UART2_TX_Pin PMOD_UART2_RX_Pin */
	GPIO_InitStruct.Pin = PMOD_UART2_CTS_Pin | PMOD_UART2_RTS_Pin
			| PMOD_UART2_TX_Pin | PMOD_UART2_RX_Pin;
	GPIO_InitStruct.Mode = GPIO_MODE_AF_PP;
	GPIO_InitStruct.Pull = GPIO_NOPULL;
	GPIO_InitStruct.Speed = GPIO_SPEED_FREQ_VERY_HIGH;
	GPIO_InitStruct.Alternate = GPIO_AF7_USART2;
	HAL_GPIO_Init(GPIOD, &GPIO_InitStruct);

	/*Configure GPIO pins : ARD_D15_Pin ARD_D14_Pin */
	GPIO_InitStruct.Pin = ARD_D15_Pin | ARD_D14_Pin;
	GPIO_InitStruct.Mode = GPIO_MODE_AF_OD;
	GPIO_InitStruct.Pull = GPIO_PULLUP;
	GPIO_InitStruct.Speed = GPIO_SPEED_FREQ_VERY_HIGH;
	GPIO_InitStruct.Alternate = GPIO_AF4_I2C1;
	HAL_GPIO_Init(GPIOB, &GPIO_InitStruct);

	/* EXTI interrupt init*/
	HAL_NVIC_SetPriority(EXTI9_5_IRQn, 0, 0);
	HAL_NVIC_EnableIRQ(EXTI9_5_IRQn);

	HAL_NVIC_SetPriority(EXTI15_10_IRQn, 0, 0);
	HAL_NVIC_EnableIRQ(EXTI15_10_IRQn);

}

void Error_Handler(void) {
}

/************************ (C) COPYRIGHT STMicroelectronics *****END OF FILE****/
